VERSION ""

NS_ :

BS_:

BU_:

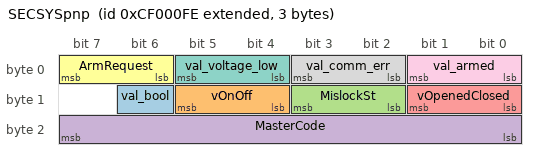
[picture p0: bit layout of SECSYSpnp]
BO_ 2364539134 SECSYSpnp: 3 Vector__XXX
 SG_ val_bool : 14|1@1+ (1,0) [0|0] "" Vector__XXX
 SG_ vOnOff : 12|2@1+ (1,0) [0|0] "" Vector__XXX
 SG_ MislockSt : 10|2@1+ (1,0) [0|0] "" Vector__XXX
 SG_ MasterCode : 16|8@1+ (1,0) [0|0] "" Vector__XXX
 SG_ vOpenedClosed : 8|2@1+ (1,0) [0|0] "" Vector__XXX
 SG_ ArmRequest : 6|2@1+ (1,0) [0|0] "" Vector__XXX
 SG_ val_voltage_low : 4|2@1+ (1,0) [0|0] "" Vector__XXX
 SG_ val_comm_err : 2|2@1+ (1,0) [0|0] "" Vector__XXX
 SG_ val_armed : 0|2@1+ (1,0) [0|0] "" Vector__XXX

CM_ "Arrival Alarm system internal communication.
$DBC storage: //depot/auto/dbc/Software_Modules\AlarmSysInternal
";
BA_DEF_ SG_  "SigType" ENUM  "Default","Range","RangeSigned","ASCII","Discrete","Control","ReferencePGN","DTC","StringDelimiter","StringLength","StringLengthControl","MessageCounter","MessageChecksum";
BA_DEF_ SG_  "GenSigEVName" STRING ;
BA_DEF_ SG_  "GenSigILSupport" ENUM  "No","Yes";
BA_DEF_ SG_  "GenSigSendType" ENUM  "Cyclic","OnWrite","OnWriteWithRepetition","OnChange","OnChangeWithRepetition","IfActive","IfActiveWithRepetition","NoSigSendType";
BA_DEF_ BO_  "GenMsgILSupport" ENUM  "No","Yes";
BA_DEF_ BU_  "NmStationAddress" INT 0 255;
BA_DEF_ BO_  "GenMsgSendType" ENUM  "cyclic","NotUsed","IfActive","NotUsed","NotUsed","NotUsed","NotUsed","NotUsed","noMsgSendType";
BA_DEF_ BO_  "GenMsgRequestable" INT 0 1;
BA_DEF_  "DBName" STRING ;
BA_DEF_  "BusType" STRING ;
BA_DEF_  "ProtocolType" STRING ;
BA_DEF_ BO_  "VFrameFormat" ENUM  "StandardCAN","ExtendedCAN","reserved","J1939PG";
BA_DEF_DEF_  "SigType" "Default";
BA_DEF_DEF_  "GenSigEVName" "Env@Nodename_@Signame";
BA_DEF_DEF_  "GenSigILSupport" "Yes";
BA_DEF_DEF_  "GenSigSendType" "NoSigSendType";
BA_DEF_DEF_  "GenMsgILSupport" "Yes";
BA_DEF_DEF_  "NmStationAddress" 254;
BA_DEF_DEF_  "GenMsgSendType" "noMsgSendType";
BA_DEF_DEF_  "GenMsgRequestable" 1;
BA_DEF_DEF_  "DBName" "";
BA_DEF_DEF_  "BusType" "CAN";
BA_DEF_DEF_  "ProtocolType" "J1939";
BA_DEF_DEF_  "VFrameFormat" "J1939PG";
BA_ "DBName" "SECSYS_pnp";
VAL_ 2364539134 vOnOff 3 "Not Available" 2 "Error" 1 "On" 0 "Off" ;
VAL_ 2364539134 MislockSt 3 "NA" 2 "Reserved" 1 "Detected" 0 "Not detected" ;
VAL_ 2364539134 vOpenedClosed 3 "NA" 2 "Reserved" 1 "Opened" 0 "Closed" ;
VAL_ 2364539134 ArmRequest 3 "NA" 2 "Reserved" 1 "Arm" 0 "Disarm" ;
VAL_ 2364539134 val_voltage_low 3 "NA" 2 "Reserved" 1 "Voltage Low" 0 "Voltage OK" ;
VAL_ 2364539134 val_comm_err 3 "NA" 2 "Reserved" 1 "Comm Error" 0 "Comm Ok" ;
VAL_ 2364539134 val_armed 3 "NA" 2 "Reserved" 1 "Armed" 0 "Disarmed" ;
